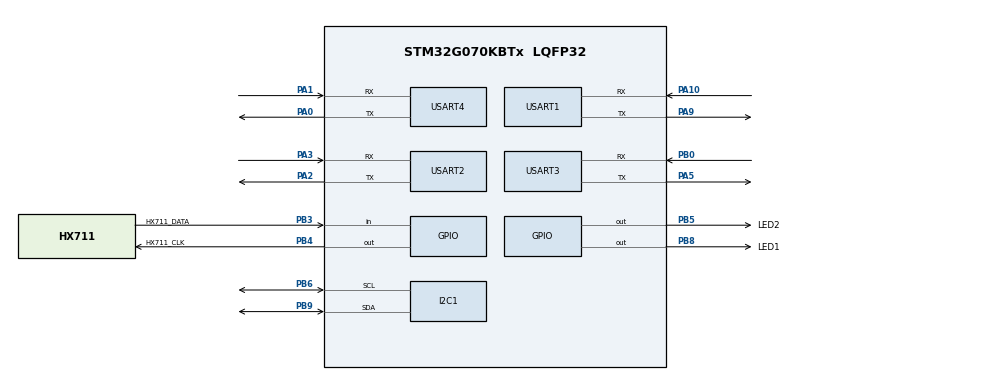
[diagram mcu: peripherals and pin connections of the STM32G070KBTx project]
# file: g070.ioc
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I2C1.Timing=0x10707DBC
Mcu.Family=STM32G0
Mcu.Name=STM32G070KBTx
Mcu.Package=LQFP32
PA0.Mode=Asynchronous
PA0.Signal=USART4_TX
PA1.Mode=Asynchronous
PA1.Signal=USART4_RX
PA10.Mode=Asynchronous
PA10.Signal=USART1_RX
PA13.Mode=Serial_Wire
PA13.Signal=SYS_SWDIO
PA14-BOOT0.Mode=Serial_Wire
PA14-BOOT0.Signal=SYS_SWCLK
PA2.Mode=Asynchronous
PA2.Signal=USART2_TX
PA3.Mode=Asynchronous
PA3.Signal=USART2_RX
PA5.Mode=Asynchronous
PA5.Signal=USART3_TX
PA9.Mode=Asynchronous
PA9.Signal=USART1_TX
PB0.Mode=Asynchronous
PB0.Signal=USART3_RX
PB3.GPIO_Label=HX711_DATA
PB3.Signal=GPIO_Input
PB4.GPIO_Label=HX711_CLK
PB4.Signal=GPIO_Output
PB5.GPIO_Label=LED2
PB5.Signal=GPIO_Output
PB6.GPIO_Pu=GPIO_PULLUP
PB6.Mode=I2C
PB6.Signal=I2C1_SCL
PB8.GPIO_Label=LED1
PB8.Signal=GPIO_Output
PB9.GPIO_Pu=GPIO_PULLUP
PB9.Mode=I2C
PB9.Signal=I2C1_SDA
ProjectManager.HeapSize=0x200
ProjectManager.StackSize=0x400
ProjectManager.TargetToolchain=EWARM V8.50
RCC.ADCFreq_Value=64000000
RCC.AHBFreq_Value=64000000
RCC.CortexFreq_Value=64000000
RCC.EXTERNAL_CLOCK_VALUE=48000
RCC.HCLKFreq_Value=64000000
RCC.HSE_VALUE=8000000
RCC.HSI_VALUE=16000000
RCC.LSE_VALUE=32768
RCC.SYSCLKFreq_VALUE=64000000
RCC.SYSCLKSource=RCC_SYSCLKSOURCE_PLLCLK
RCC.VCOOutputFreq_Value=128000000
USART1.VirtualMode-Asynchronous=VM_ASYNC
USART2.VirtualMode-Asynchronous=VM_ASYNC
USART3.VirtualMode-Asynchronous=VM_ASYNC
USART4.VirtualMode-Asynchronous=VM_ASYNC
VP_SYS_VS_DBSignals.Mode=DisableDeadBatterySignals
board=custom

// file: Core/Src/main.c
/* USER CODE BEGIN Header */
/**
  ******************************************************************************
  * @file           : main.c
  * @brief          : Main program body
  ******************************************************************************
  * @attention
  *
  * <h2><center>&copy; Copyright (c) 2020 STMicroelectronics.
  * All rights reserved.</center></h2>
  *
  * This software component is licensed by ST under BSD 3-Clause license,
  * the "License"; You may not use this file except in compliance with the
  * License. You may obtain a copy of the License at:
  *                        opensource.org/licenses/BSD-3-Clause
  *
  ******************************************************************************
  */
/* USER CODE END Header */
#include "main.h"

void SystemClock_Config(void);
static void MX_GPIO_Init(void);
static void MX_I2C1_Init(void);
static void MX_USART1_UART_Init(void);
static void MX_USART2_UART_Init(void);
static void MX_USART3_UART_Init(void);
static void MX_USART4_UART_Init(void);

/* USER CODE BEGIN 0 */
uint32_t i = 0;

/* USER CODE END 0 */

int main(void)
{

  /* MCU Configuration--------------------------------------------------------*/

  /* Reset of all peripherals, Initializes the Flash interface and the Systick. */

  LL_APB2_GRP1_EnableClock(LL_APB2_GRP1_PERIPH_SYSCFG);
  LL_APB1_GRP1_EnableClock(LL_APB1_GRP1_PERIPH_PWR);

  /* System interrupt init*/

  /** Disable the internal Pull-Up in Dead Battery pins of UCPD peripheral
  */
  LL_SYSCFG_DisableDBATT(LL_SYSCFG_UCPD1_STROBE | LL_SYSCFG_UCPD2_STROBE);

  /* Configure the system clock */
  SystemClock_Config();

  /* Initialize all configured peripherals */
  MX_GPIO_Init();
  MX_I2C1_Init();
  MX_USART1_UART_Init();
  MX_USART2_UART_Init();
  MX_USART3_UART_Init();
  MX_USART4_UART_Init();

  /* Infinite loop */
  /* USER CODE BEGIN WHILE */
#pragma ide diagnostic ignored "EndlessLoop"
  while (1)
  {
      i++;
      LL_GPIO_TogglePin(GPIOB,  LL_GPIO_PIN_8);
      LL_GPIO_SetOutputPin(GPIOB,  LL_GPIO_PIN_5);
      LL_mDelay(300);
      LL_GPIO_ResetOutputPin(GPIOB,  LL_GPIO_PIN_5);
      LL_mDelay(300);
    /* USER CODE END WHILE */

  }
}

void SystemClock_Config(void)
{
  LL_FLASH_SetLatency(LL_FLASH_LATENCY_2);
  while(LL_FLASH_GetLatency() != LL_FLASH_LATENCY_2)
  {
  }

  /* HSI configuration and activation */
  LL_RCC_HSI_Enable();
  while(LL_RCC_HSI_IsReady() != 1)
  {
  }

  /* Main PLL configuration and activation */
  LL_RCC_PLL_ConfigDomain_SYS(LL_RCC_PLLSOURCE_HSI, LL_RCC_PLLM_DIV_1, 8, LL_RCC_PLLR_DIV_2);
  LL_RCC_PLL_Enable();
  LL_RCC_PLL_EnableDomain_SYS();
  while(LL_RCC_PLL_IsReady() != 1)
  {
  }

  /* Set AHB prescaler*/
  LL_RCC_SetAHBPrescaler(LL_RCC_SYSCLK_DIV_1);

  /* Sysclk activation on the main PLL */
  LL_RCC_SetSysClkSource(LL_RCC_SYS_CLKSOURCE_PLL);
  while(LL_RCC_GetSysClkSource() != LL_RCC_SYS_CLKSOURCE_STATUS_PLL)
  {
  }

  /* Set APB1 prescaler*/
  LL_RCC_SetAPB1Prescaler(LL_RCC_APB1_DIV_1);
  LL_Init1msTick(64000000);
  /* Update CMSIS variable (which can be updated also through SystemCoreClockUpdate function) */
  LL_SetSystemCoreClock(64000000);
  LL_RCC_SetUSARTClockSource(LL_RCC_USART1_CLKSOURCE_PCLK1);
  LL_RCC_SetUSARTClockSource(LL_RCC_USART2_CLKSOURCE_PCLK1);
  LL_RCC_SetI2CClockSource(LL_RCC_I2C1_CLKSOURCE_PCLK1);
}

static void MX_I2C1_Init(void)
{

  LL_I2C_InitTypeDef I2C_InitStruct = {0};

  LL_GPIO_InitTypeDef GPIO_InitStruct = {0};

  LL_IOP_GRP1_EnableClock(LL_IOP_GRP1_PERIPH_GPIOB);
  /**I2C1 GPIO Configuration
  PB6   ------> I2C1_SCL
  PB7   ------> I2C1_SDA
  */
  GPIO_InitStruct.Pin = LL_GPIO_PIN_6;
  GPIO_InitStruct.Mode = LL_GPIO_MODE_ALTERNATE;
  GPIO_InitStruct.Speed = LL_GPIO_SPEED_FREQ_LOW;
  GPIO_InitStruct.OutputType = LL_GPIO_OUTPUT_OPENDRAIN;
  GPIO_InitStruct.Pull = LL_GPIO_PULL_UP;
  GPIO_InitStruct.Alternate = LL_GPIO_AF_6;
  LL_GPIO_Init(GPIOB, &GPIO_InitStruct);

  GPIO_InitStruct.Pin = LL_GPIO_PIN_7;
  GPIO_InitStruct.Mode = LL_GPIO_MODE_ALTERNATE;
  GPIO_InitStruct.Speed = LL_GPIO_SPEED_FREQ_LOW;
  GPIO_InitStruct.OutputType = LL_GPIO_OUTPUT_OPENDRAIN;
  GPIO_InitStruct.Pull = LL_GPIO_PULL_UP;
  GPIO_InitStruct.Alternate = LL_GPIO_AF_6;
  LL_GPIO_Init(GPIOB, &GPIO_InitStruct);

  /* Peripheral clock enable */
  LL_APB1_GRP1_EnableClock(LL_APB1_GRP1_PERIPH_I2C1);

  /** I2C Initialization
  */
  I2C_InitStruct.PeripheralMode = LL_I2C_MODE_I2C;
  I2C_InitStruct.Timing = 0x10707DBC;
  I2C_InitStruct.AnalogFilter = LL_I2C_ANALOGFILTER_ENABLE;
  I2C_InitStruct.DigitalFilter = 0;
  I2C_InitStruct.OwnAddress1 = 0;
  I2C_InitStruct.TypeAcknowledge = LL_I2C_ACK;
  I2C_InitStruct.OwnAddrSize = LL_I2C_OWNADDRESS1_7BIT;
  LL_I2C_Init(I2C1, &I2C_InitStruct);
  LL_I2C_EnableAutoEndMode(I2C1);
  LL_I2C_SetOwnAddress2(I2C1, 0, LL_I2C_OWNADDRESS2_NOMASK);
  LL_I2C_DisableOwnAddress2(I2C1);
  LL_I2C_DisableGeneralCall(I2C1);
  LL_I2C_EnableClockStretching(I2C1);

}

static void MX_USART1_UART_Init(void)
{

  LL_USART_InitTypeDef USART_InitStruct = {0};

  LL_GPIO_InitTypeDef GPIO_InitStruct = {0};

  /* Peripheral clock enable */
  LL_APB2_GRP1_EnableClock(LL_APB2_GRP1_PERIPH_USART1);

  LL_IOP_GRP1_EnableClock(LL_IOP_GRP1_PERIPH_GPIOA);
  /**USART1 GPIO Configuration
  PA9   ------> USART1_TX
  PA10   ------> USART1_RX
  */
  GPIO_InitStruct.Pin = LL_GPIO_PIN_9;
  GPIO_InitStruct.Mode = LL_GPIO_MODE_ALTERNATE;
  GPIO_InitStruct.Speed = LL_GPIO_SPEED_FREQ_LOW;
  GPIO_InitStruct.OutputType = LL_GPIO_OUTPUT_PUSHPULL;
  GPIO_InitStruct.Pull = LL_GPIO_PULL_NO;
  GPIO_InitStruct.Alternate = LL_GPIO_AF_1;
  LL_GPIO_Init(GPIOA, &GPIO_InitStruct);

  GPIO_InitStruct.Pin = LL_GPIO_PIN_10;
  GPIO_InitStruct.Mode = LL_GPIO_MODE_ALTERNATE;
  GPIO_InitStruct.Speed = LL_GPIO_SPEED_FREQ_LOW;
  GPIO_InitStruct.OutputType = LL_GPIO_OUTPUT_PUSHPULL;
  GPIO_InitStruct.Pull = LL_GPIO_PULL_NO;
  GPIO_InitStruct.Alternate = LL_GPIO_AF_1;
  LL_GPIO_Init(GPIOA, &GPIO_InitStruct);

  USART_InitStruct.PrescalerValue = LL_USART_PRESCALER_DIV1;
  USART_InitStruct.BaudRate = 115200;
  USART_InitStruct.DataWidth = LL_USART_DATAWIDTH_8B;
  USART_InitStruct.StopBits = LL_USART_STOPBITS_1;
  USART_InitStruct.Parity = LL_USART_PARITY_NONE;
  USART_InitStruct.TransferDirection = LL_USART_DIRECTION_TX_RX;
  USART_InitStruct.HardwareFlowControl = LL_USART_HWCONTROL_NONE;
  USART_InitStruct.OverSampling = LL_USART_OVERSAMPLING_16;
  LL_USART_Init(USART1, &USART_InitStruct);
  LL_USART_SetTXFIFOThreshold(USART1, LL_USART_FIFOTHRESHOLD_1_8);
  LL_USART_SetRXFIFOThreshold(USART1, LL_USART_FIFOTHRESHOLD_1_8);
  LL_USART_DisableFIFO(USART1);
  LL_USART_ConfigAsyncMode(USART1);

  LL_USART_Enable(USART1);

  /* Polling USART1 initialisation */
  while((!(LL_USART_IsActiveFlag_TEACK(USART1))) || (!(LL_USART_IsActiveFlag_REACK(USART1))))
  {
  }

}

static void MX_USART2_UART_Init(void)
{

  LL_USART_InitTypeDef USART_InitStruct = {0};

  LL_GPIO_InitTypeDef GPIO_InitStruct = {0};

  /* Peripheral clock enable */
  LL_APB1_GRP1_EnableClock(LL_APB1_GRP1_PERIPH_USART2);

  LL_IOP_GRP1_EnableClock(LL_IOP_GRP1_PERIPH_GPIOA);
  /**USART2 GPIO Configuration
  PA2   ------> USART2_TX
  PA3   ------> USART2_RX
  */
  GPIO_InitStruct.Pin = LL_GPIO_PIN_2;
  GPIO_InitStruct.Mode = LL_GPIO_MODE_ALTERNATE;
  GPIO_InitStruct.Speed = LL_GPIO_SPEED_FREQ_LOW;
  GPIO_InitStruct.OutputType = LL_GPIO_OUTPUT_PUSHPULL;
  GPIO_InitStruct.Pull = LL_GPIO_PULL_NO;
  GPIO_InitStruct.Alternate = LL_GPIO_AF_1;
  LL_GPIO_Init(GPIOA, &GPIO_InitStruct);

  GPIO_InitStruct.Pin = LL_GPIO_PIN_3;
  GPIO_InitStruct.Mode = LL_GPIO_MODE_ALTERNATE;
  GPIO_InitStruct.Speed = LL_GPIO_SPEED_FREQ_LOW;
  GPIO_InitStruct.OutputType = LL_GPIO_OUTPUT_PUSHPULL;
  GPIO_InitStruct.Pull = LL_GPIO_PULL_NO;
  GPIO_InitStruct.Alternate = LL_GPIO_AF_1;
  LL_GPIO_Init(GPIOA, &GPIO_InitStruct);

  USART_InitStruct.PrescalerValue = LL_USART_PRESCALER_DIV1;
  USART_InitStruct.BaudRate = 115200;
  USART_InitStruct.DataWidth = LL_USART_DATAWIDTH_8B;
  USART_InitStruct.StopBits = LL_USART_STOPBITS_1;
  USART_InitStruct.Parity = LL_USART_PARITY_NONE;
  USART_InitStruct.TransferDirection = LL_USART_DIRECTION_TX_RX;
  USART_InitStruct.HardwareFlowControl = LL_USART_HWCONTROL_NONE;
  USART_InitStruct.OverSampling = LL_USART_OVERSAMPLING_16;
  LL_USART_Init(USART2, &USART_InitStruct);
  LL_USART_SetTXFIFOThreshold(USART2, LL_USART_FIFOTHRESHOLD_1_8);
  LL_USART_SetRXFIFOThreshold(USART2, LL_USART_FIFOTHRESHOLD_1_8);
  LL_USART_DisableFIFO(USART2);
  LL_USART_ConfigAsyncMode(USART2);

  LL_USART_Enable(USART2);

  /* Polling USART2 initialisation */
  while((!(LL_USART_IsActiveFlag_TEACK(USART2))) || (!(LL_USART_IsActiveFlag_REACK(USART2))))
  {
  }

}

static void MX_USART3_UART_Init(void)
{

  LL_USART_InitTypeDef USART_InitStruct = {0};

  LL_GPIO_InitTypeDef GPIO_InitStruct = {0};

  /* Peripheral clock enable */
  LL_APB1_GRP1_EnableClock(LL_APB1_GRP1_PERIPH_USART3);

  LL_IOP_GRP1_EnableClock(LL_IOP_GRP1_PERIPH_GPIOB);
  LL_IOP_GRP1_EnableClock(LL_IOP_GRP1_PERIPH_GPIOA);
  /**USART3 GPIO Configuration
  PB9   ------> USART3_RX
  PA5   ------> USART3_TX
  */
  GPIO_InitStruct.Pin = LL_GPIO_PIN_9;
  GPIO_InitStruct.Mode = LL_GPIO_MODE_ALTERNATE;
  GPIO_InitStruct.Speed = LL_GPIO_SPEED_FREQ_LOW;
  GPIO_InitStruct.OutputType = LL_GPIO_OUTPUT_PUSHPULL;
  GPIO_InitStruct.Pull = LL_GPIO_PULL_NO;
  GPIO_InitStruct.Alternate = LL_GPIO_AF_4;
  LL_GPIO_Init(GPIOB, &GPIO_InitStruct);

  GPIO_InitStruct.Pin = LL_GPIO_PIN_5;
  GPIO_InitStruct.Mode = LL_GPIO_MODE_ALTERNATE;
  GPIO_InitStruct.Speed = LL_GPIO_SPEED_FREQ_LOW;
  GPIO_InitStruct.OutputType = LL_GPIO_OUTPUT_PUSHPULL;
  GPIO_InitStruct.Pull = LL_GPIO_PULL_NO;
  GPIO_InitStruct.Alternate = LL_GPIO_AF_4;
  LL_GPIO_Init(GPIOA, &GPIO_InitStruct);

  USART_InitStruct.PrescalerValue = LL_USART_PRESCALER_DIV1;
  USART_InitStruct.BaudRate = 115200;
  USART_InitStruct.DataWidth = LL_USART_DATAWIDTH_8B;
  USART_InitStruct.StopBits = LL_USART_STOPBITS_1;
  USART_InitStruct.Parity = LL_USART_PARITY_NONE;
  USART_InitStruct.TransferDirection = LL_USART_DIRECTION_TX_RX;
  USART_InitStruct.HardwareFlowControl = LL_USART_HWCONTROL_NONE;
  USART_InitStruct.OverSampling = LL_USART_OVERSAMPLING_16;
  LL_USART_Init(USART3, &USART_InitStruct);
  LL_USART_ConfigAsyncMode(USART3);

  LL_USART_Enable(USART3);

  /* Polling USART3 initialisation */
  while((!(LL_USART_IsActiveFlag_TEACK(USART3))) || (!(LL_USART_IsActiveFlag_REACK(USART3))))
  {
  }

}

static void MX_USART4_UART_Init(void)
{

  LL_USART_InitTypeDef USART_InitStruct = {0};

  LL_GPIO_InitTypeDef GPIO_InitStruct = {0};

  /* Peripheral clock enable */
  LL_APB1_GRP1_EnableClock(LL_APB1_GRP1_PERIPH_USART4);

  LL_IOP_GRP1_EnableClock(LL_IOP_GRP1_PERIPH_GPIOA);
  /**USART4 GPIO Configuration
  PA0   ------> USART4_TX
  PA1   ------> USART4_RX
  */
  GPIO_InitStruct.Pin = LL_GPIO_PIN_0;
  GPIO_InitStruct.Mode = LL_GPIO_MODE_ALTERNATE;
  GPIO_InitStruct.Speed = LL_GPIO_SPEED_FREQ_LOW;
  GPIO_InitStruct.OutputType = LL_GPIO_OUTPUT_PUSHPULL;
  GPIO_InitStruct.Pull = LL_GPIO_PULL_NO;
  GPIO_InitStruct.Alternate = LL_GPIO_AF_4;
  LL_GPIO_Init(GPIOA, &GPIO_InitStruct);

  GPIO_InitStruct.Pin = LL_GPIO_PIN_1;
  GPIO_InitStruct.Mode = LL_GPIO_MODE_ALTERNATE;
  GPIO_InitStruct.Speed = LL_GPIO_SPEED_FREQ_LOW;
  GPIO_InitStruct.OutputType = LL_GPIO_OUTPUT_PUSHPULL;
  GPIO_InitStruct.Pull = LL_GPIO_PULL_NO;
  GPIO_InitStruct.Alternate = LL_GPIO_AF_4;
  LL_GPIO_Init(GPIOA, &GPIO_InitStruct);

  USART_InitStruct.PrescalerValue = LL_USART_PRESCALER_DIV1;
  USART_InitStruct.BaudRate = 115200;
  USART_InitStruct.DataWidth = LL_USART_DATAWIDTH_8B;
  USART_InitStruct.StopBits = LL_USART_STOPBITS_1;
  USART_InitStruct.Parity = LL_USART_PARITY_NONE;
  USART_InitStruct.TransferDirection = LL_USART_DIRECTION_TX_RX;
  USART_InitStruct.HardwareFlowControl = LL_USART_HWCONTROL_NONE;
  USART_InitStruct.OverSampling = LL_USART_OVERSAMPLING_16;
  LL_USART_Init(USART4, &USART_InitStruct);
  LL_USART_ConfigAsyncMode(USART4);

  LL_USART_Enable(USART4);

  /* Polling USART4 initialisation */
  while((!(LL_USART_IsActiveFlag_TEACK(USART4))) || (!(LL_USART_IsActiveFlag_REACK(USART4))))
  {
  }

}

static void MX_GPIO_Init(void)
{
  LL_GPIO_InitTypeDef GPIO_InitStruct = {0};

  /* GPIO Ports Clock Enable */
  LL_IOP_GRP1_EnableClock(LL_IOP_GRP1_PERIPH_GPIOB);
  LL_IOP_GRP1_EnableClock(LL_IOP_GRP1_PERIPH_GPIOC);
  LL_IOP_GRP1_EnableClock(LL_IOP_GRP1_PERIPH_GPIOA);

  /**/
  LL_GPIO_ResetOutputPin(LED2_GPIO_Port, LED2_Pin);

  /**/
  LL_GPIO_ResetOutputPin(LED1_GPIO_Port, LED1_Pin);

  /**/
  GPIO_InitStruct.Pin = LED2_Pin;
  GPIO_InitStruct.Mode = LL_GPIO_MODE_OUTPUT;
  GPIO_InitStruct.Speed = LL_GPIO_SPEED_FREQ_LOW;
  GPIO_InitStruct.OutputType = LL_GPIO_OUTPUT_PUSHPULL;
  GPIO_InitStruct.Pull = LL_GPIO_PULL_NO;
  LL_GPIO_Init(LED2_GPIO_Port, &GPIO_InitStruct);

  /**/
  GPIO_InitStruct.Pin = LED1_Pin;
  GPIO_InitStruct.Mode = LL_GPIO_MODE_OUTPUT;
  GPIO_InitStruct.Speed = LL_GPIO_SPEED_FREQ_LOW;
  GPIO_InitStruct.OutputType = LL_GPIO_OUTPUT_PUSHPULL;
  GPIO_InitStruct.Pull = LL_GPIO_PULL_NO;
  LL_GPIO_Init(LED1_GPIO_Port, &GPIO_InitStruct);

}

void Error_Handler(void)
{
}

/************************ (C) COPYRIGHT STMicroelectronics *****END OF FILE****/
